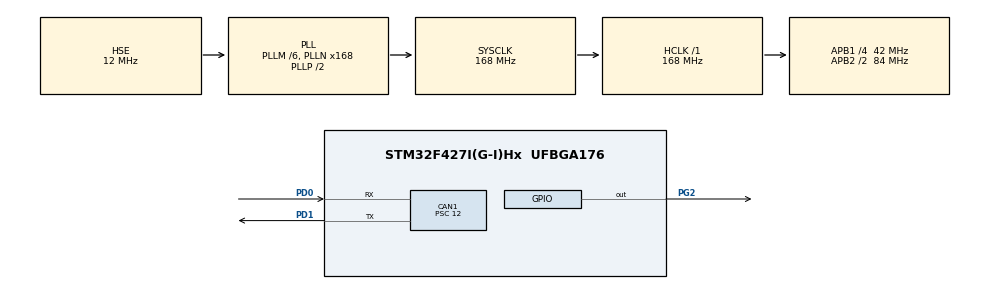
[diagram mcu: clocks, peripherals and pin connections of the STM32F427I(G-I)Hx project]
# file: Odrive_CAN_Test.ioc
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CAN1.BS1=CAN_BS1_7TQ
CAN1.BS2=CAN_BS2_6TQ
CAN1.CalculateBaudRate=250000
CAN1.CalculateTimeBit=4000
CAN1.CalculateTimeQuantum=285.7142857142857
CAN1.Prescaler=12
Mcu.Family=STM32F4
Mcu.Name=STM32F427I(G-I)Hx
Mcu.Package=UFBGA176
NVIC.CAN1_RX0_IRQn=true\:0\:0\:false\:false\:true\:true\:true\:true
NVIC.PriorityGroup=NVIC_PRIORITYGROUP_4
PA13.Mode=Serial_Wire
PA13.Signal=SYS_JTMS-SWDIO
PA14.Mode=Serial_Wire
PA14.Signal=SYS_JTCK-SWCLK
PD0.Mode=CAN_Activate
PD0.Signal=CAN1_RX
PD1.Mode=CAN_Activate
PD1.Signal=CAN1_TX
PG2.Signal=GPIO_Output
PH0/OSC_IN.Mode=HSE-External-Oscillator
PH0/OSC_IN.Signal=RCC_OSC_IN
PH1/OSC_OUT.Mode=HSE-External-Oscillator
PH1/OSC_OUT.Signal=RCC_OSC_OUT
ProjectManager.HeapSize=0x200
ProjectManager.StackSize=0x400
ProjectManager.TargetToolchain=Makefile
RCC.48MHZClocksFreq_Value=84000000
RCC.AHBFreq_Value=168000000
RCC.APB1CLKDivider=RCC_HCLK_DIV4
RCC.APB1Freq_Value=42000000
RCC.APB1TimFreq_Value=84000000
RCC.APB2CLKDivider=RCC_HCLK_DIV2
RCC.APB2Freq_Value=84000000
RCC.APB2TimFreq_Value=168000000
RCC.CortexFreq_Value=168000000
RCC.HCLKFreq_Value=168000000
RCC.HSE_VALUE=12000000
RCC.HSI_VALUE=16000000
RCC.LSE_VALUE=32768
RCC.PLLM=6
RCC.PLLN=168
RCC.PLLSourceVirtual=RCC_PLLSOURCE_HSE
RCC.SYSCLKFreq_VALUE=168000000
RCC.SYSCLKSource=RCC_SYSCLKSOURCE_PLLCLK
RCC.VCOOutputFreq_Value=336000000
board=custom

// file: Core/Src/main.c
/* USER CODE BEGIN Header */
/**
 ******************************************************************************
 * @file           : main.c
 * @brief          : Main program body
 ******************************************************************************
 * @attention
 *
 * Copyright (c) 2024 STMicroelectronics.
 * All rights reserved.
 *
 * This software is licensed under terms that can be found in the LICENSE file
 * in the root directory of this software component.
 * If no LICENSE file comes with this software, it is provided AS-IS.
 *
 ******************************************************************************
 */
/* USER CODE END Header */
#include "main.h"
#include "can.h"
#include "gpio.h"

/* USER CODE BEGIN Includes */
#include "odrive.h"
/* USER CODE END Includes */

void SystemClock_Config(void);

int main(void)
{

  /* MCU Configuration--------------------------------------------------------*/

  /* Reset of all peripherals, Initializes the Flash interface and the Systick. */
  HAL_Init();

  /* Configure the system clock */
  SystemClock_Config();

  /* Initialize all configured peripherals */
  MX_GPIO_Init();
  MX_CAN1_Init();
  /* USER CODE BEGIN 2 */
  odrive_init();
  odrive_axis[0].AXIS_ID = 0x10;
  odrive_axis[1].AXIS_ID = 0x01;
  HAL_Delay(100);
  // Set_Controller_Modes(odrive_axis[0], VELOCITY_CONTROL, PASSTHROUGH);
  // Set_Axis_Requested_State(odrive_axis[0], CLOSED_LOOP_CONTROL);
  Set_Input_Vel(odrive_axis[0], 2, 0);
  // HAL_Delay(1000);
  // Set_Input_Vel(odrive_axis[0], 0, 0);
  /* USER CODE END 2 */

  /* Infinite loop */
  while (1)
  {

    /* USER CODE BEGIN 3 */
    Set_Input_Vel(odrive_axis[0], 2, 0);
    HAL_Delay(10);
  }
  /* USER CODE END 3 */
}

void SystemClock_Config(void)
{
  RCC_OscInitTypeDef RCC_OscInitStruct = {0};
  RCC_ClkInitTypeDef RCC_ClkInitStruct = {0};

  /** Configure the main internal regulator output voltage
   */
  __HAL_RCC_PWR_CLK_ENABLE();
  __HAL_PWR_VOLTAGESCALING_CONFIG(PWR_REGULATOR_VOLTAGE_SCALE1);

  /** Initializes the RCC Oscillators according to the specified parameters
   * in the RCC_OscInitTypeDef structure.
   */
  RCC_OscInitStruct.OscillatorType = RCC_OSCILLATORTYPE_HSE;
  RCC_OscInitStruct.HSEState = RCC_HSE_ON;
  RCC_OscInitStruct.PLL.PLLState = RCC_PLL_ON;
  RCC_OscInitStruct.PLL.PLLSource = RCC_PLLSOURCE_HSE;
  RCC_OscInitStruct.PLL.PLLM = 6;
  RCC_OscInitStruct.PLL.PLLN = 168;
  RCC_OscInitStruct.PLL.PLLP = RCC_PLLP_DIV2;
  RCC_OscInitStruct.PLL.PLLQ = 4;
  if (HAL_RCC_OscConfig(&RCC_OscInitStruct) != HAL_OK)
  {
    Error_Handler();
  }

  /** Initializes the CPU, AHB and APB buses clocks
   */
  RCC_ClkInitStruct.ClockType = RCC_CLOCKTYPE_HCLK | RCC_CLOCKTYPE_SYSCLK | RCC_CLOCKTYPE_PCLK1 | RCC_CLOCKTYPE_PCLK2;
  RCC_ClkInitStruct.SYSCLKSource = RCC_SYSCLKSOURCE_PLLCLK;
  RCC_ClkInitStruct.AHBCLKDivider = RCC_SYSCLK_DIV1;
  RCC_ClkInitStruct.APB1CLKDivider = RCC_HCLK_DIV4;
  RCC_ClkInitStruct.APB2CLKDivider = RCC_HCLK_DIV2;

  if (HAL_RCC_ClockConfig(&RCC_ClkInitStruct, FLASH_LATENCY_5) != HAL_OK)
  {
    Error_Handler();
  }
}

void Error_Handler(void)
{
  __disable_irq();
  while (1)
  {
  }
}
